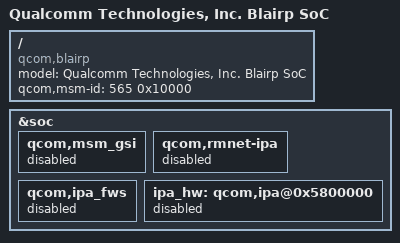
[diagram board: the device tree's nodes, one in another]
/dts-v1/;

#include "blair.dtsi"

/ {
	model = "Qualcomm Technologies, Inc. Blairp SoC";
	compatible = "qcom,blairp";
	qcom,msm-id = <565 0x10000>;
};

&soc {
	qcom,msm_gsi {
		status = "disabled";
	};

	qcom,rmnet-ipa {
		status = "disabled";
	};

	qcom,ipa_fws {
		status = "disabled";
	};

	ipa_hw: qcom,ipa@0x5800000 {
		status = "disabled";
	};

};
